# STM32F40x register map
File version: 1.5
Registers are 32-bit, read-write, reset 0x0 unless marked. A register's access mark holds for its fields unless they carry their own. Offsets are from the block's base; [hi:lo] are bit positions; {n}, {i} and the like mark numbered series.

## SDIO（安全数字IO） — 安全数字输入输出：SD 卡/MMC 接口 | Secure digital input/output interface
Base 0x40012C00
0x00 POWER（电源） — 电源控制 | power control register
  [1:0] PWRCTRL
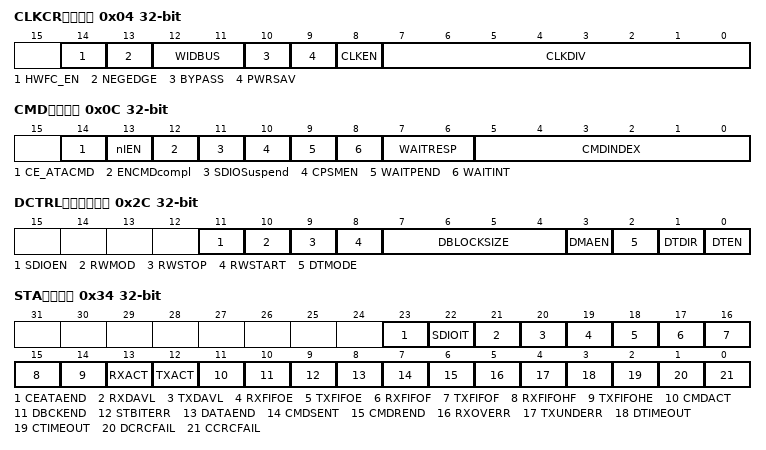
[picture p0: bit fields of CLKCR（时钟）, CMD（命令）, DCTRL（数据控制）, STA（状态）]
0x04 CLKCR（时钟） — 时钟分频/总线宽度 | SDI clock control register
  [14] HWFC_EN — HW Flow Control enable
  [13] NEGEDGE — SDIO_CK dephasing selection bit
  [12:11] WIDBUS — Wide bus mode enable bit
  [10] BYPASS — Clock divider bypass enable bit
  [9] PWRSAV — Power saving configuration bit
  [8] CLKEN — Clock enable bit
  [7:0] CLKDIV — Clock divide factor
0x08 ARG（参数） — 命令参数 | argument register
  [31:0] CMDARG — Command argument
0x0C CMD（命令） — 命令索引与类型 | command register
  [14] CE_ATACMD — CE-ATA command
  [13] nIEN — not Interrupt Enable
  [12] ENCMDcompl — Enable CMD completion
  [11] SDIOSuspend — SD I/O suspend command
  [10] CPSMEN — Command path state machine (CPSM) Enable bit
  [9] WAITPEND — CPSM Waits for ends of data transfer (CmdPend internal signal).
  [8] WAITINT — CPSM waits for interrupt request
  [7:6] WAITRESP — Wait for response bits
  [5:0] CMDINDEX — Command index
0x10 RESPCMD（响应命令） ro — 最后响应命令索引 | command response register
  [5:0] RESPCMD — Response command index
{0x10+4i} RESP{i}（响应{i}） ro (i=1..4) — 卡响应 {i} | response 1..4 register
  [31:0] CARDSTATUS{i} — see Table 132.
0x24 DTIMER（数据定时器） — 数据超时 | data timer register
  [31:0] DATATIME — Data timeout period
0x28 DLEN（数据长度） — 传输字节数 | data length register
  [24:0] DATALENGTH — Data length value
0x2C DCTRL（数据控制） — 传输使能/方向/模式 | data control register
  [11] SDIOEN — SD I/O enable functions
  [10] RWMOD — Read wait mode
  [9] RWSTOP — Read wait stop
  [8] RWSTART — Read wait start
  [7:4] DBLOCKSIZE — Data block size
  [3] DMAEN — DMA enable bit
  [2] DTMODE — Data transfer mode selection 1: Stream or SDIO multibyte data transfer.
  [1] DTDIR — Data transfer direction selection
  [0] DTEN
0x30 DCOUNT（数据剩余） ro — 剩余传输计数 | data counter register
  [24:0] DATACOUNT — Data count value
0x34 STA（状态） ro — 状态标志 | status register
  [23] CEATAEND — CE-ATA command completion signal received for CMD61
  [22] SDIOIT — SDIO interrupt received
  [21] RXDAVL — Data available in receive FIFO
  [20] TXDAVL — Data available in transmit FIFO
  [19] RXFIFOE — Receive FIFO empty
  [18] TXFIFOE — Transmit FIFO empty
  [17] RXFIFOF — Receive FIFO full
  [16] TXFIFOF — Transmit FIFO full
  [15] RXFIFOHF — Receive FIFO half full: there are at least 8 words in the FIFO
  [14] TXFIFOHE — Transmit FIFO half empty: at least 8 words can be written into the FIFO
  [13] RXACT — Data receive in progress
  [12] TXACT — Data transmit in progress
  [11] CMDACT — Command transfer in progress
  [10] DBCKEND — Data block sent/received (CRC check passed)
  [9] STBITERR — Start bit not detected on all data signals in wide bus mode
  [8] DATAEND — Data end (data counter, SDIDCOUNT, is zero)
  [7] CMDSENT — Command sent (no response required)
  [6] CMDREND — Command response received (CRC check passed)
  [5] RXOVERR — Received FIFO overrun error
  [4] TXUNDERR — Transmit FIFO underrun error
  [3] DTIMEOUT — Data timeout
  [2] CTIMEOUT — Command response timeout
  [1] DCRCFAIL — Data block sent/received (CRC check failed)
  [0] CCRCFAIL — Command response received (CRC check failed)
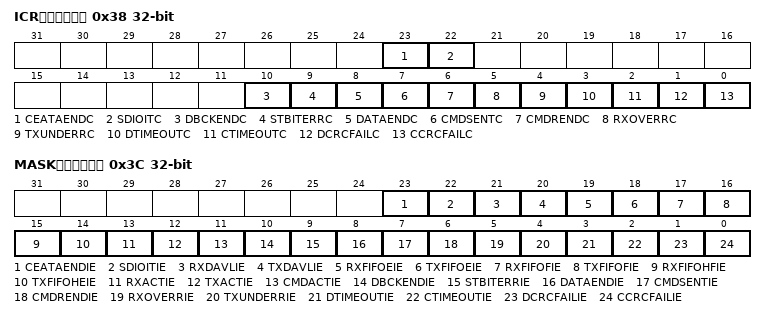
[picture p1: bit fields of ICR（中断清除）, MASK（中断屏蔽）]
0x38 ICR（中断清除） — 清除中断标志 | interrupt clear register
  [23] CEATAENDC — CEATAEND flag clear bit
  [22] SDIOITC — SDIOIT flag clear bit
  [10] DBCKENDC — DBCKEND flag clear bit
  [9] STBITERRC — STBITERR flag clear bit
  [8] DATAENDC — DATAEND flag clear bit
  [7] CMDSENTC — CMDSENT flag clear bit
  [6] CMDRENDC — CMDREND flag clear bit
  [5] RXOVERRC — RXOVERR flag clear bit
  [4] TXUNDERRC — TXUNDERR flag clear bit
  [3] DTIMEOUTC — DTIMEOUT flag clear bit
  [2] CTIMEOUTC — CTIMEOUT flag clear bit
  [1] DCRCFAILC — DCRCFAIL flag clear bit
  [0] CCRCFAILC — CCRCFAIL flag clear bit
0x3C MASK（中断屏蔽） — 中断屏蔽 | mask register
  [23] CEATAENDIE — CE-ATA command completion signal received interrupt enable
  [22] SDIOITIE — SDIO mode interrupt received interrupt enable
  [21] RXDAVLIE — Data available in Rx FIFO interrupt enable
  [20] TXDAVLIE — Data available in Tx FIFO interrupt enable
  [19] RXFIFOEIE — Rx FIFO empty interrupt enable
  [18] TXFIFOEIE — Tx FIFO empty interrupt enable
  [17] RXFIFOFIE — Rx FIFO full interrupt enable
  [16] TXFIFOFIE — Tx FIFO full interrupt enable
  [15] RXFIFOHFIE — Rx FIFO half full interrupt enable
  [14] TXFIFOHEIE — Tx FIFO half empty interrupt enable
  [13] RXACTIE — Data receive acting interrupt enable
  [12] TXACTIE — Data transmit acting interrupt enable
  [11] CMDACTIE — Command acting interrupt enable
  [10] DBCKENDIE — Data block end interrupt enable
  [9] STBITERRIE — Start bit error interrupt enable
  [8] DATAENDIE — Data end interrupt enable
  [7] CMDSENTIE — Command sent interrupt enable
  [6] CMDRENDIE — Command response received interrupt enable
  [5] RXOVERRIE — Rx FIFO overrun error interrupt enable
  [4] TXUNDERRIE — Tx FIFO underrun error interrupt enable
  [3] DTIMEOUTIE — Data timeout interrupt enable
  [2] CTIMEOUTIE — Command timeout interrupt enable
  [1] DCRCFAILIE — Data CRC fail interrupt enable
  [0] CCRCFAILIE — Command CRC fail interrupt enable
0x48 FIFOCNT（FIFO计数） ro — FIFO 剩余字数 | FIFO counter register
  [23:0] FIFOCOUNT — Remaining number of words to be written to or read from the FIFO.
0x80 FIFO（FIFO缓冲） — 数据 FIFO | data FIFO register
  [31:0] FIFOData — Receive and transmit FIFO data
